# platform_designer_hps_system_hps_0_hps register map
Vendor: default_vendor.com; File version: 0.0
Registers are 32-bit, read-write, reset 0x0 unless marked. A register's access mark holds for its fields unless they carry their own. Offsets are from the block's base; [hi:lo] are bit positions; {n}, {i} and the like mark numbered series; 'fields as' and 'values as' point back to an identical list.

## can0 — Registers in the CAN Controller module NOTE: These descriptions apply only to SoC devices that support the CAN module.
Base 0xFFC00000
Same registers: can1 0xFFC01000
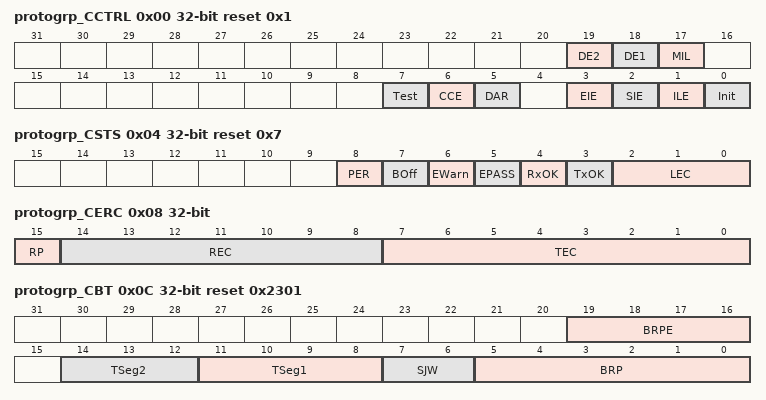
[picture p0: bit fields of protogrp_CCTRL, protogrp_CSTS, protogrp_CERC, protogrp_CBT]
0x00 protogrp_CCTRL reset 0x1 — Control Register
  [19] DE2 — DMA Enable for IF2
    0=Disabled; 1=Enabled
  [18] DE1 — DMA Enable for IF1
    0=Disabled; 1=Enabled
  [17] MIL — Message Object Interrupt Line Enable
    0=Disabled; 1=Enabled
  [7] Test — Test Mode Enable
    0=Disabled; 1=TestMode
  [6] CCE — Configuration Change Enable
    0=NoWrAcc; 1=WrAcc
  [5] DAR — Disable Automatic Retransmission
    0=Enabled; 1=Disabled
  [3] EIE — Error Interrupt Enable
    0=Disabled; 1=Enabled
  [2] SIE — Status Interrupt Enable
    0=Disabled; 1=Enabled
  [1] ILE — Module Interrupt Line Enable
    0=Disabled; 1=Enabled
  [0] Init — Initialization Note: Due to the synchronization mechanism between the two clock domains, there may be a delay until the value written to CCTRL.Init can be read back. Therefore the programmer has to assure that the previous value written to CCTRL.Init has been accepted by reading CCTRL.Init before setting CCTRL.Init to a new value. Note: The Bus_Off recovery sequence (see CAN Specification Rev. 2.0) cannot be shortened by setting or resetting CCTRL.Init. If the device goes Bus_Off, it will set CCTRL.Init of its own accord, stopping all bus activities. Once CCTRL.Init has been cleared by the CPU, the device will then wait for 129 occurrences of Bus Idle (129 * 11 consecutive recessive bits) before resuming normal operations. At the end of the Bus_Off recovery sequence, the Error Management Counters will be reset. During the waiting time after the resetting of CCTRL.Init, each time a sequence of 11 recessive bits has been monitored, a Bit0Error code is written to the Status Register, enabling the CPU to readily check up whether the CAN bus is stuck at dominant or continuously disturbed and to monitor the proceeding of the us_Off recovery sequence.
    0=Normal; 1=Start
0x04 protogrp_CSTS ro reset 0x7 — Status Register
  [8] PER — Parity Error Detected
    0=None; 1=ErrorDetected
  [7] BOff — Bus_Off Status
    0=NotBusOff; 1=BusOff
  [6] EWarn — Warning Status
    0=BelowLimit; 1=AboveLimit
  [5] EPASS — Error Passive
    0=Active; 1=Passive
  [4] RxOK — Received a Message Successfully
    0=NoRxOk; 1=RxOk
  [3] TxOK — Transmitted a Message Successfully
    0=NoTxOk; 1=TxOk
  [2:0] LEC — The LEC field holds a code which indicates the type of the last error to occur on the CAN bus. This field will be cleared to 0 when a message has been transferred (reception or transmission) without error.
    0=NoError; 1=StuffError; 2=FormError; 3=AckError; 4=Bit1Error; 5=Bit0Error; 6=CRCError; 7=NoChange
0x08 protogrp_CERC ro — Error Counter Register
  [15] RP
    0=Below; 1=Reached
  [14:8] REC — Actual state of the Receive Error Counter. Values between 0 and 127.
  [7:0] TEC — Actual state of the Transmit Error Counter. Values between 0 and 255.
0x0C protogrp_CBT reset 0x2301 — This register is only writable if bits CCTRL.CCE and CCTRL.Init are set. The CAN bit time may be programed in the range of [4 .. 25] time quanta. The CAN time quantum may be programmed in the range of [1 .. 1024] CAN_CLK periods. For details see Application Note 001 "Configuration of Bit Timing". The actual interpretation by the hardware of this value is such that one more than the value programmed here is used. TSeg1 is the sum of Prop_Seg and Phase_Seg1. TSeg2 is Phase_Seg2. Therefore the length of the bit time is (programmed values) [TSeg1 + TSeg2 + 3] tq or (functional values) [Sync_Seg + Prop_Seg + Phase_Seg1 + Phase_Seg2] tq.
  [19:16] BRPE — By programming BRPE the Baud Rate Prescaler can be extended to values up to 1023. The actual interpretation by the hardware is that one more than the value programmed by BRPE (MSBs) and BRP (LSBs) is used.
  [14:12] TSeg2 — Valid values for TSeg2 are [0 .. 7].
  [11:8] TSeg1 — Valid values for TSeg1 are [1 .. 15].
  [7:6] SJW — Valid programmed values are [0 .. 3]. The actual interpretation by the hardware of this value is such that one more than the value programmed here is used.
  [5:0] BRP — The value by which the oscillator frequency is divided for generating the bit time quanta. The bit time is built up from a multiple of this quanta. Valid values for the Baud Rate Prescaler are [0 .. 63]. The actual interpretation by the hardware of this value is such that one more than the value programmed here is used.
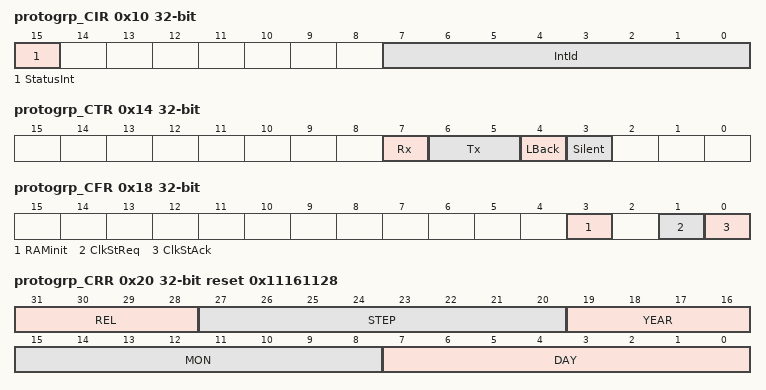
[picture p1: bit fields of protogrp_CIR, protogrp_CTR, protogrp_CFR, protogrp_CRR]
0x10 protogrp_CIR ro — If several interrupts are pending, the CAN Interrupt Register will point to the pending interrupt with the highest priority, disregarding their chronological order. An interrupt remains pending until the CPU has cleared it. If IntID is different from 0x00 and CCTRL.MIL is set, the interrupt port CAN_INT_MO is active. The interrupt port remains active until IntID is back to value 0x00 (the cause of the interrupt is reset) or until CCTRL.MIL is reset. If CCTRL.ILE is set and CCTRL.MIL is reseted the Message Object interrupts will be routed to interrupt port CAN_INT_STATUS. The interrupt port remains active until IntID is back to value 0x00 (the cause of the interrupt is reset) or until CCTRL.MIL is set or CCTRL.ILE is reset. The Message Object's interrupt priority decreases with increasing message number. A message interrupt is cleared by clearing the Message Object's IntPnd bit.
  [15] StatusInt — The Status Interrupt is cleared by reading the Status Register.
  [7:0] IntId — 0x00 No Message Object interrupt is pending. 0x01-0x80 Number of Message Object which caused the interrupt. 0x81-0xFF unused.
0x14 protogrp_CTR (reset mask 0xFFFFFF7F) — The Test Mode is entered by setting bit CCTRL.Test to one. In Test Mode the bits EXL, Tx1, Tx0, LBack and Silent in the Test Register are writable. Bit Rx monitors the state of pin CAN_RXD and therefore is only readable. All Test Register functions are disabled when bit Test is reset to zero. Loop Back Mode and CAN_TXD Control Mode are hardware test modes, not to be used by application programs. Note: This register is only writable if bit CCTRL.Test is set.
  [7] Rx ro — Monitors the actual value of the CAN_RXD pin.
    0=Dominant; 1=Recessive
  [6:5] Tx — Controls CAN_TXD pin. Setting to non-zero disturbs message transfer.
    0=Reset; 1=Sample; 2=Dominant; 3=Recessive
  [4] LBack — Loop Back Mode
    0=Disabled; 1=Enabled
  [3] Silent — Silent Mode
    0=Normal; 1=Silent
0x18 protogrp_CFR — The Function Register controls the features RAM_Initialisation and Power_Down also by application register. The CAN module can be prepared for Power_Down by setting the port CAN_CLKSTOP_REQ to one or writing to CFR.ClkStReq a one. The power down state is left by setting port CAN_CLKSTOP_REQ to zero or writing to CFR.ClkStReq a zero, acknowledged by CAN_CLKSTOP_ACK is going to zero as well as CFR.ClkStAck. The CCTRL.Init bit is left one and has to be written by the application to re-enable CAN transfers. Note: It's recommended to use either the ports CAN_CLKSTOP_REQ and CAN_CLKSTOP_ACK or the CCTRL.ClkStReq and CFR.ClkStAck. The application CFR.ClkStReq showsalso the actual status of the portCAN_CLKSTOP_REQ.
  [3] RAMinit — Request for automatic RAM Initialization
    0=NoAuto; 1=StartAuto
  [1] ClkStReq — Clock Stop Request
  [0] ClkStAck ro — Clock Stop Acknowledgement
0x20 protogrp_CRR ro reset 0x11161128 — Core Release Register
  [31:28] REL, [27:20] STEP, [19:16] YEAR, [15:8] MON, [7:0] DAY
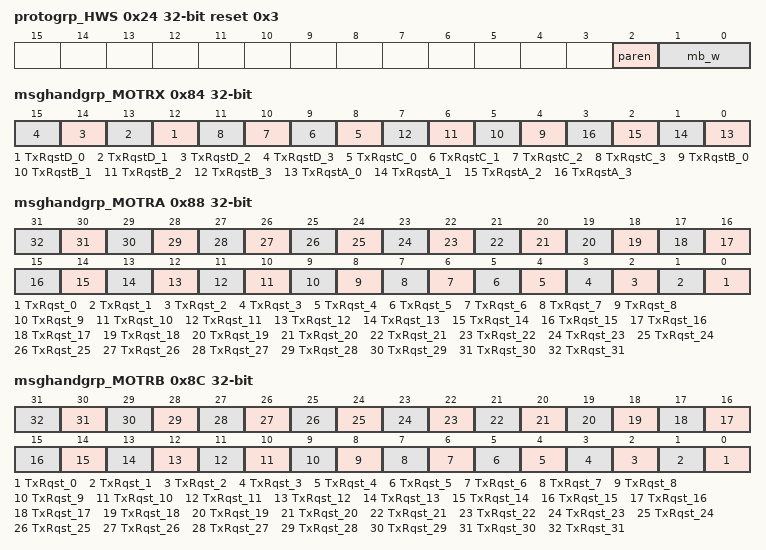
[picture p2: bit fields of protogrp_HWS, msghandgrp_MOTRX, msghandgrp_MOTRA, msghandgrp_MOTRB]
0x24 protogrp_HWS ro reset 0x3 — Hardware Configuration Status Register
  [2] paren — Parity Generation
    0=NotPresent; 1=Present
  [1:0] mb_w — Message Buffer Count
    0=MsgObjs16; 1=MsgObjs32; 2=MsgObjs64; 3=MsgObjs128
0x84 msghandgrp_MOTRX ro — Reading this register allows the CPU to quickly detect if any of the transmission request bits in each of the MOTRA, MOTRB, MOTRC, and MOTRD Transmission Request Registers are set.
  [all] fields
    0=NotWaiting; 1=Pending
  [n+12] TxRqstD_{n} (n=0..3) — Each bit in this field is a logical OR of a byte of the MOTRD register. Array index i corresponds to byte i of the MOTRD register.
  [n+8] TxRqstC_{n} (n=0..3) — Each bit in this field is a logical OR of a byte of the MOTRC register. Array index i corresponds to byte i of the MOTRC register.
  [n+4] TxRqstB_{n} (n=0..3) — Each bit in this field is a logical OR of a byte of the MOTRB register. Array index i corresponds to byte i of the MOTRB register.
  [n] TxRqstA_{n} (n=0..3) — Each bit in this field is a logical OR of a byte of the MOTRA register. Array index i corresponds to byte i of the MOTRA register.
0x88 msghandgrp_MOTRA ro — Transmission request bits for Message Objects 1 to 32. By reading the TxRqst bits, the CPU can check for which Message Object a Transmission Request is pending. The TxRqst bit of a specific Message Object can be set/reset by the CPU via the IFx Message Interface Registers or set by the Message Handler after reception of a Remote Frame or reset by the Message Handler after a successful transmission.
  [all] fields
    0=NotWaiting; 1=Pending
  [n] TxRqst_{n} (n=0..31) — Transmission request bits for Message Objects 1 to 32. Array index i corresponds to Message Object i+1.
0x8C msghandgrp_MOTRB ro — Transmission request bits for Message Objects 33 to 64. By reading the TxRqst bits, the CPU can check for which Message Object a Transmission Request is pending. The TxRqst bit of a specific Message Object can be set/reset by the CPU via the IFx Message Interface Registers or set by the Message Handler after reception of a Remote Frame or reset by the Message Handler after a successful transmission.
  [all] fields
    0=NotWaiting; 1=Pending
  [n] TxRqst_{n} (n=0..31) — Transmission request bits for Message Objects 33 to 64. Array index i corresponds to Message Object i+33.
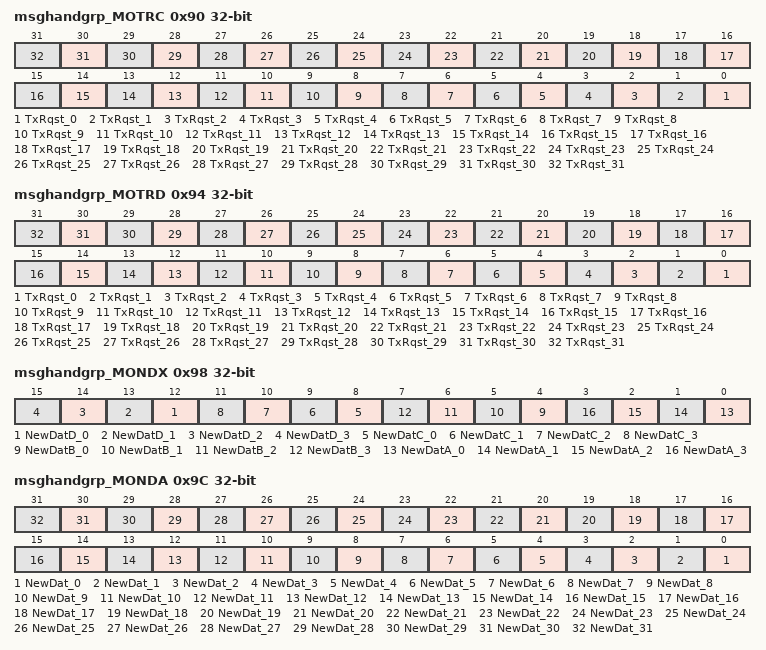
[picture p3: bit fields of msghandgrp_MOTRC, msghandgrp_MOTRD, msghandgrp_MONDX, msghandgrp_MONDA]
0x90 msghandgrp_MOTRC ro — Transmission request bits for Message Objects 65 to 96. By reading the TxRqst bits, the CPU can check for which Message Object a Transmission Request is pending. The TxRqst bit of a specific Message Object can be set/reset by the CPU via the IFx Message Interface Registers or set by the Message Handler after reception of a Remote Frame or reset by the Message Handler after a successful transmission.
  [all] fields
    0=NotWaiting; 1=Pending
  [n] TxRqst_{n} (n=0..31) — Transmission request bits for Message Objects 65 to 96. Array index i corresponds to Message Object i+65.
0x94 msghandgrp_MOTRD ro — Transmission request bits for Message Objects 97 to 128. By reading the TxRqst bits, the CPU can check for which Message Object a Transmission Request is pending. The TxRqst bit of a specific Message Object can be set/reset by the CPU via the IFx Message Interface Registers or set by the Message Handler after reception of a Remote Frame or reset by the Message Handler after a successful transmission.
  [all] fields
    0=NotWaiting; 1=Pending
  [n] TxRqst_{n} (n=0..31) — Transmission request bits for Message Objects 97 to 128. Array index i corresponds to Message Object i+97.
0x98 msghandgrp_MONDX ro — Reading this register allows the CPU to quickly detect if any of the new data bits in each of the MONDA, MONDB, MONDC, and MONDD New Data Registers are set.
  [all] fields
    0=NotWritten; 1=Written
  [n+12] NewDatD_{n} (n=0..3) — Each bit in this field is a logical OR of a byte of the MONDD register. Array index i corresponds to byte i of the MONDD register.
  [n+8] NewDatC_{n} (n=0..3) — Each bit in this field is a logical OR of a byte of the MONDC register. Array index i corresponds to byte i of the MONDC register.
  [n+4] NewDatB_{n} (n=0..3) — Each bit in this field is a logical OR of a byte of the MONDB register. Array index i corresponds to byte i of the MONDB register.
  [n] NewDatA_{n} (n=0..3) — Each bit in this field is a logical OR of a byte of the MONDA register. Array index i corresponds to byte i of the MONDA register.
0x9C msghandgrp_MONDA ro — New data bits for Message Objects 1 to 32. By reading the NewDat bits, the CPU can check for which Message Object the data portion was updated. The NewDat bit of a specific Message Object can be set/reset by the CPU via the IFx Message Interface Registers or set by the Message Handler after reception of a Data Frame or reset by the Message Handler at start of a transmission.
  [all] fields
    0=NotWritten; 1=Written
  [n] NewDat_{n} (n=0..31) — New data bits for Message Objects 1 to 32. Array index i corresponds to Message Object i+1.
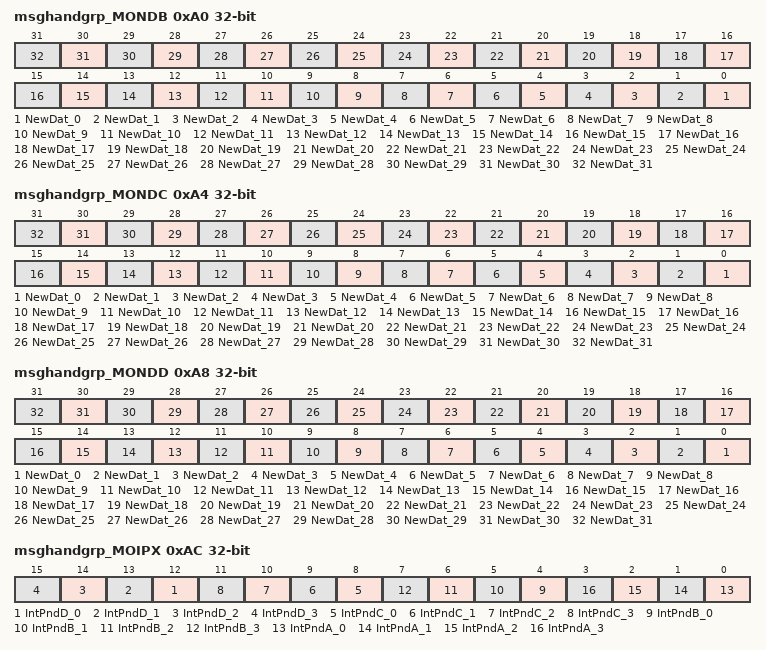
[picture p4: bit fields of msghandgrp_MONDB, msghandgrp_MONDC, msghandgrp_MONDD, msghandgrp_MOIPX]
0xA0 msghandgrp_MONDB ro — New data bits for Message Objects 33 to 64. By reading the NewDat bits, the CPU can check for which Message Object the data portion was updated. The NewDat bit of a specific Message Object can be set/reset by the CPU via the IFx Message Interface Registers or set by the Message Handler after reception of a Data Frame or reset by the Message Handler at start of a transmission.
  [all] fields
    0=NotWritten; 1=Written
  [n] NewDat_{n} (n=0..31) — New data bits for Message Objects 33 to 64. Array index i corresponds to Message Object i+33.
0xA4 msghandgrp_MONDC ro — New data bits for Message Objects 65 to 96. By reading the NewDat bits, the CPU can check for which Message Object the data portion was updated. The NewDat bit of a specific Message Object can be set/reset by the CPU via the IFx Message Interface Registers or set by the Message Handler after reception of a Data Frame or reset by the Message Handler at start of a transmission.
  [all] fields
    0=NotWritten; 1=Written
  [n] NewDat_{n} (n=0..31) — New data bits for Message Objects 65 to 96. Array index i corresponds to Message Object i+65.
0xA8 msghandgrp_MONDD ro — New data bits for Message Objects 97 to 128. By reading the NewDat bits, the CPU can check for which Message Object the data portion was updated. The NewDat bit of a specific Message Object can be set/reset by the CPU via the IFx Message Interface Registers or set by the Message Handler after reception of a Data Frame or reset by the Message Handler at start of a transmission.
  [all] fields
    0=NotWritten; 1=Written
  [n] NewDat_{n} (n=0..31) — New data bits for Message Objects 97 to 128. Array index i corresponds to Message Object i+97.
0xAC msghandgrp_MOIPX ro — Reading this register allows the CPU to quickly detect if any of the interrupt pending bits in each of the MOIPA, MOIPB, MOIPC, and MOIPD Interrupt Pending Registers are set.
  [all] fields
    0=NotSrc; 1=Src
  [n+12] IntPndD_{n} (n=0..3) — Each bit in this field is a logical OR of a byte of the MOIPD register. Array index i corresponds to byte i of the MOIPD register.
  [n+8] IntPndC_{n} (n=0..3) — Each bit in this field is a logical OR of a byte of the MOIPC register. Array index i corresponds to byte i of the MOIPC register.
  [n+4] IntPndB_{n} (n=0..3) — Each bit in this field is a logical OR of a byte of the MOIPB register. Array index i corresponds to byte i of the MOIPB register.
  [n] IntPndA_{n} (n=0..3) — Each bit in this field is a logical OR of a byte of the MOIPA register. Array index i corresponds to byte i of the MOIPA register.
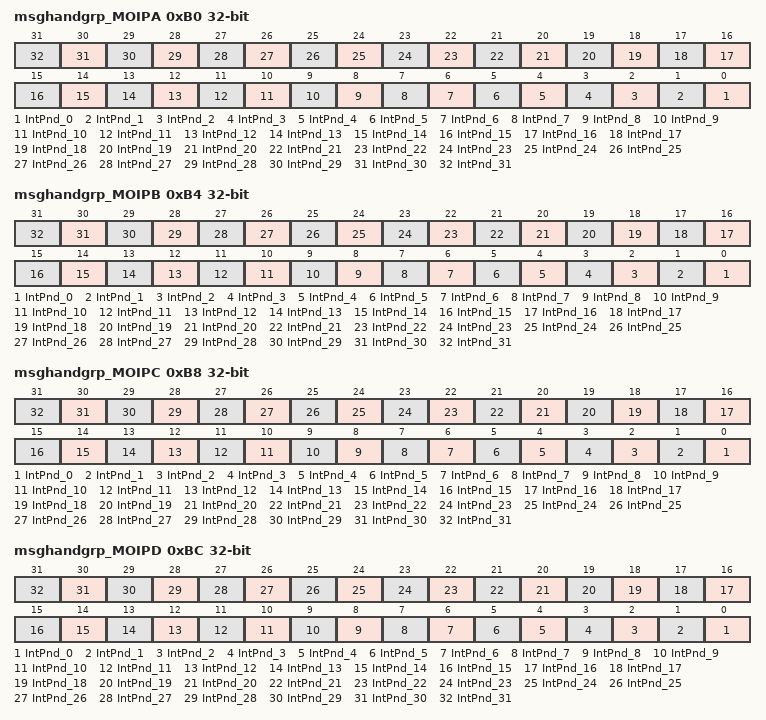
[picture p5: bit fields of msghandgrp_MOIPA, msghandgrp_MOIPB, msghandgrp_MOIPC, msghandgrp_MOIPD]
0xB0 msghandgrp_MOIPA ro — Interrupt pending bits for Message Objects 1 to 32. By reading the IntPnd bits, the CPU can check for which Message Object an interrupt is pending. The IntPnd bit of a specific Message Object can be set/reset by the CPU via the IFx Message Interface Registers or set by the Message Handler after reception or after a successful transmission of a frame. This will also affect the valid of IntID in the Interrupt Register.
  [all] fields
    0=NotSrc; 1=Src
  [n] IntPnd_{n} (n=0..31) — Interrupt pending bits for Message Objects 1 to 32. Array index i corresponds to Message Object i+1.
0xB4 msghandgrp_MOIPB ro — Interrupt pending bits for Message Objects 33 to 64. By reading the IntPnd bits, the CPU can check for which Message Object an interrupt is pending. The IntPnd bit of a specific Message Object can be set/reset by the CPU via the IFx Message Interface Registers or set by the Message Handler after reception or after a successful transmission of a frame. This will also affect the valid of IntID in the Interrupt Register.
  [all] fields
    0=NotSrc; 1=Src
  [n] IntPnd_{n} (n=0..31) — Interrupt pending bits for Message Objects 33 to 64. Array index i corresponds to Message Object i+33.
0xB8 msghandgrp_MOIPC ro — Interrupt pending bits for Message Objects 65 to 96. By reading the IntPnd bits, the CPU can check for which Message Object an interrupt is pending. The IntPnd bit of a specific Message Object can be set/reset by the CPU via the IFx Message Interface Registers or set by the Message Handler after reception or after a successful transmission of a frame. This will also affect the valid of IntID in the Interrupt Register.
  [all] fields
    0=NotSrc; 1=Src
  [n] IntPnd_{n} (n=0..31) — Interrupt pending bits for Message Objects 65 to 96. Array index i corresponds to Message Object i+65.
0xBC msghandgrp_MOIPD ro — Interrupt pending bits for Message Objects 97 to 128. By reading the IntPnd bits, the CPU can check for which Message Object an interrupt is pending. The IntPnd bit of a specific Message Object can be set/reset by the CPU via the IFx Message Interface Registers or set by the Message Handler after reception or after a successful transmission of a frame. This will also affect the valid of IntID in the Interrupt Register.
  [all] fields
    0=NotSrc; 1=Src
  [n] IntPnd_{n} (n=0..31) — Interrupt pending bits for Message Objects 97 to 128. Array index i corresponds to Message Object i+97.
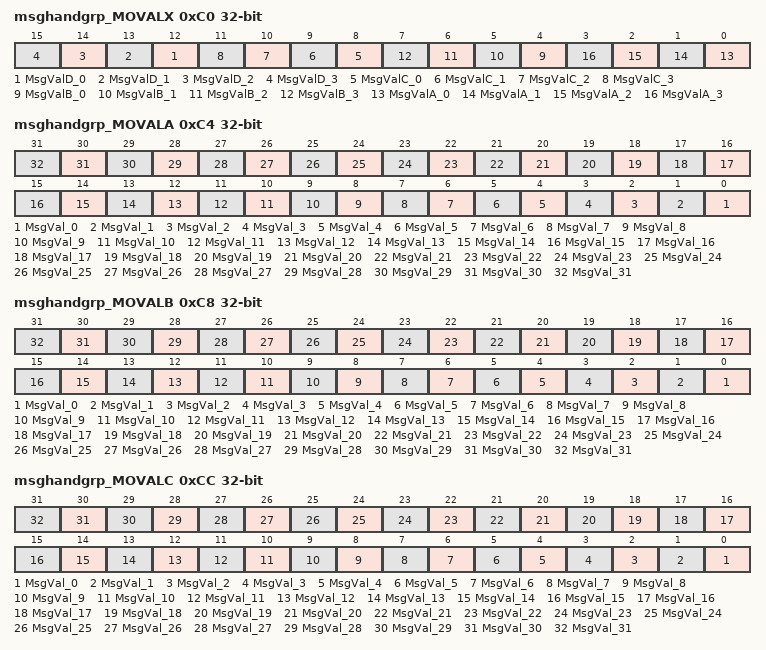
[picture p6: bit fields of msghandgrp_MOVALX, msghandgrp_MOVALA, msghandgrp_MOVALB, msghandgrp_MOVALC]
0xC0 msghandgrp_MOVALX ro — Reading this register allows the CPU to quickly detect if any of the message valid bits in each of the MOVALA, MOVALB, MOVALC, and MOVALD Message Valid Registers are set.
  [all] fields
    0=Ignored; 1=Considered
  [n+12] MsgValD_{n} (n=0..3) — Each bit in this field is a logical OR of a byte of the MOVALD register. Array index i corresponds to byte i of the MOVALD register.
  [n+8] MsgValC_{n} (n=0..3) — Each bit in this field is a logical OR of a byte of the MOVALC register. Array index i corresponds to byte i of the MOVALC register.
  [n+4] MsgValB_{n} (n=0..3) — Each bit in this field is a logical OR of a byte of the MOVALB register. Array index i corresponds to byte i of the MOVALB register.
  [n] MsgValA_{n} (n=0..3) — Each bit in this field is a logical OR of a byte of the MOVALA register. Array index i corresponds to byte i of the MOVALA register.
0xC4 msghandgrp_MOVALA ro — Message valid bits for Message Objects 1 to 32. By reading the MsgVal bits, the CPU can check for which Message Object is valid. The MsgVal bit of a specific Message Object can be set/reset by the CPU via the IFx Message Interface Registers.
  [all] fields
    0=Ignored; 1=Considered
  [n] MsgVal_{n} (n=0..31) — Message valid bits for Message Objects 1 to 32. Array index i corresponds to Message Object i+1.
0xC8 msghandgrp_MOVALB ro — Message valid bits for Message Objects 33 to 64. By reading the MsgVal bits, the CPU can check for which Message Object is valid. The MsgVal bit of a specific Message Object can be set/reset by the CPU via the IFx Message Interface Registers.
  [all] fields
    0=Ignored; 1=Considered
  [n] MsgVal_{n} (n=0..31) — Message valid bits for Message Objects 33 to 64. Array index i corresponds to Message Object i+33.
0xCC msghandgrp_MOVALC ro — Message valid bits for Message Objects 65 to 96. By reading the MsgVal bits, the CPU can check for which Message Object is valid. The MsgVal bit of a specific Message Object can be set/reset by the CPU via the IFx Message Interface Registers.
  [all] fields
    0=Ignored; 1=Considered
  [n] MsgVal_{n} (n=0..31) — Message valid bits for Message Objects 65 to 96. Array index i corresponds to Message Object i+65.
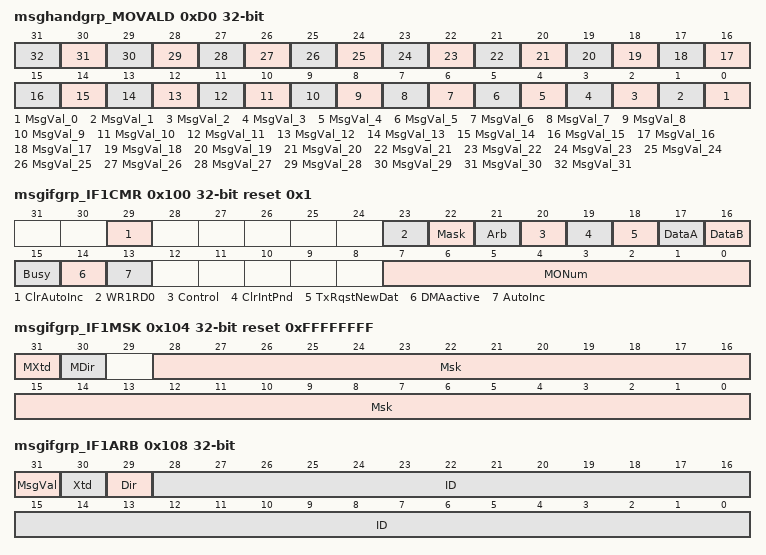
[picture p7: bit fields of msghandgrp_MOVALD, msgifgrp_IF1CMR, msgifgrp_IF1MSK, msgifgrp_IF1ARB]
0xD0 msghandgrp_MOVALD ro — Message valid bits for Message Objects 97 to 128. By reading the MsgVal bits, the CPU can check for which Message Object is valid. The MsgVal bit of a specific Message Object can be set/reset by the CPU via the IFx Message Interface Registers.
  [all] fields
    0=Ignored; 1=Considered
  [n] MsgVal_{n} (n=0..31) — Message valid bits for Message Objects 97 to 128. Array index i corresponds to Message Object i+97.
0x100 msgifgrp_IF1CMR reset 0x1 — The control bits of the IF1/2 Command Register specify the transfer direction and select which portions of the Message Object should be transferred. A message transfer is started as soon as the CPU has written the message number to the low byte of the Command Request Register and IFxCMR.AutoInc is zero. With this write operation, the IFxCMR.Busy bit is automatically set to 1 to notify the CPU that a transfer is in progress. After a wait time of 2 to 8 HOST_CLK periods, the transfer between theInterface Register and the Message RAM has been completed and the IFxCMR.Busy bit is cleared to 0. The upper limit of the wait time occurs when the message transfer coincides with a CAN message transmission, acceptance filtering, or message storage. If the CPU writes to both Command Registers consecutively (requests a second transfer while another transfer is already in progress), the second transfer starts when the first one is completed. Note: While Busy bit of IF1/2 Command Register is one, IF1/2 Register Set is write protected.
  [29] ClrAutoInc — Clear the AutoInc bit without starting a transfer
    0=NoClear; 1=Clear
  [23] WR1RD0 — Write / Read Transfer
    0=Read; 1=Write
  [22] Mask — Write Direction: 0= Mask bits unchanged. 1= transfer Identifier Mask + MDir + MXtd to Message Object. Read Direction: 0= Mask bits unchanged. 1= transfer Identifier Mask + MDir + MXtd to IFxMSK Register.
  [21] Arb — Write Direction: 0= Arbitration bits unchanged. 1= transfer Identifier + Dir + Xtd + MsgVal to Message Object. Read Direction: 0= Arbitration bits unchanged. 1= transfer Identifier + Dir + Xtd + MsgVal to IFxARB Register.
  [20] Control — Write Direction: 0= Control Bits unchanged. 1= transfer Control Bits to Message Object. Note: If IFxCMR.TxRqst/NewDat bit is set, bits IFxMCTR.TxRqst and IFxMCTR.NewDat will be ignored. Read Direction: 0= Control Bits unchanged. 1= transfer Control Bits to IFxMCTR Register.
  [19] ClrIntPnd — Write Direction: Has no influence to Message Object at write transfer. Note: When writing to a Message Object, this bit is ignored and copying of IntPnd flag from IFx Control Register to Message RAM could only be controlled by IFxMTR.IntPnd bit. Read Direction: 0= IntPnd bit remains unchanged. 1= clear IntPnd bit in the Message Object.
  [18] TxRqstNewDat — Write Direction: 0= TxRqst and NewDat bit will be handled according IFxMCTR.NewDat bit and IFxMCTR.TxRqst bit. 1= set TxRqst and NewDat in Message Object to one Note: If a CAN transmission is requested by setting IFxCMR.TxRqst/NewDat, the TxRqst and NewDat bits in the Message Object will be set to one independently of the values in IFxMCTR. Read Direction: 0= NewDat bit remains unchanged. 1= clear NewDat bit in the Message Object. Note: A read access to a Message Object can be combined with the reset of the control bits IntPnd and NewDat. The values of these bits transferred to the IFxMCTR always reflect the status before resetting them.
  [17] DataA — Write Direction: 0= Data Bytes 0-3 unchanged. 1= transfer Data Bytes 0-3 to Message Object. Read Direction: 0= Data Bytes 0-3 unchanged. 1= transfer Data Bytes 0-3 to IFxDA.
  [16] DataB — Write Direction: 0= Data Bytes 4-7 unchanged. 1= transfer Data Bytes 4-7 to Message Object. Read Direction: 0= Data Bytes 4-7 unchanged. 1= transfer Data Bytes 4-7 to IFxDB. Note: The speed of the message transfer does not depend on how many bytes are transferred.
  [15] Busy ro — Busy Flag
    0=Done; 1=Writing
  [14] DMAactive — Activation of DMA feature for subsequent internal IFx Register Set
    0=Passive; 1=Initiated
  [13] AutoInc — Automatic Increment of Message Object Number The behavior of the Message Object Number increment depends on the Transfer Direction, IFxCMR.WR1RD0. * Read: The first transfer will be initiated (Busy Bit will set) at write of IFxCMR.MONum. The Message Object Number will be incremented and the next Message Object will be transferred from Message Object RAM to Interface Registers after a read access of Data-Byte 7. * Write: The first as well as each other transfer will be started after write access to Data- Byte7. The Message Object Number will be incremented after successful transfer from the Interface Registers to the Message Object RAM. Always after successful transfer the Busy Bit will be reset. In combination with DMAactive the port CAN_IFxDMA is set, too. Note: If the direction is configured as Read a write access to Data-Byte 7 will not start any transfer, as well as if the direction is configured as Write a read access to Data-Byte 7 will not start any transfer. At transfer direction Read each read of Data-Byte 7 will start a transfer until IFxCMR.AutoInc is reset. To aware of resetting a NewDat bit of the following message object, the application has to reset IFxCMR.AutoInc before reading the Data-Byte 7 of the last message object which will be read.
    0=Disabled; 1=Enabled
  [7:0] MONum — 0x01-0x80 Valid Message Number, the Message Object in the Message RAM is selected for data transfer (up to 128 MsgObj). 0x00 Not a valid Message Number, interpreted as 0x80. 0x81-0xFF Not a valid Message Number, interpreted as 0x01-0x7F. Note: When an invalid Message Number is written to IFxCMR.MONum which is higher than the last Message Object number, a modulo addressing will occur.When e.g. accessing Message Object 33 in a CAN module with 32 Message Objects only, the Message Object 1 will be accessed instead.
0x104 msgifgrp_IF1MSK reset 0xFFFFFFFF — The Message Object Mask Bits together with the arbitration bits are used for acceptance filtering of incoming messages. Note: While IFxCMR.Busy bit is one, the IF1/2 Register Set is write protected.
  [31] MXtd — When 11-bit (standard) Identifiers are used for a Message Object, the identifiers of received Data Frames are written into bits ID28 to ID18. For acceptance filtering, only these bits together with mask bits Msk28 to Msk18 are considered.
    0=NoAcceptEffect; 1=AcceptEffect
  [30] MDir
    0=NoAcceptEffect; 1=AcceptEffect
  [28:0] Msk — 0 = The corresponding bit in the identifier of the message object cannot inhibit the match in the acceptance filtering. 1 = The corresponding identifier bit is used for acceptance filtering.
0x108 msgifgrp_IF1ARB — The Arbitration Registers ID28-0, Xtd, and Dir are used to define the identifier and type of outgoing messages and are used (together with the mask registers Msk28-0, MXtd, and MDir) for acceptance filtering of incoming messages. A received message is stored into the valid Message Object with matching identifier and Direction=receive (Data Frame) or Direction=transmit (Remote Frame). Extended frames can be stored only in Message Objects with Xtd = one, standard frames in Message Objects with Xtd = zero. If a received message (Data Frame or Remote Frame) matches with more than one valid Message Object, it is stored into that with the lowest message number.
  [31] MsgVal — The CPU must reset the MsgVal bit of all unused Messages Objects during the initialization before it resets bit Init in the CAN Control Register. MsgVal must also be reset if the Messages Object is no longer used in operation. For reconfiguration of Message Objects during normal operation.
    0=Ignored; 1=Considered
  [30] Xtd — Extended Identifier
    0=Standard; 1=Extended
  [29] Dir — Message Direction
    0=Rx; 1=Tx
  [28:0] ID — ID28 - ID0 29-bit Identifier (Extended Frame). ID28 - ID18 11-bit Identifier (Standard Frame).
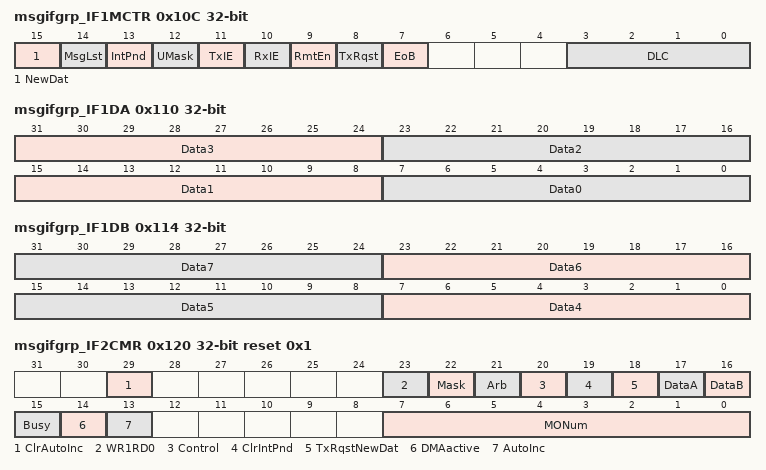
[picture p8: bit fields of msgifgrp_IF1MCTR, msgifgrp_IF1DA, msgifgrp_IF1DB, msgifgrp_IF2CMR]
0x10C msgifgrp_IF1MCTR — The Arbitration Registers ID28-0, Xtd, and Dir are used to define the identifier and type of outgoing messages and are used (together with the mask registers Msk28-0, MXtd, and MDir) for acceptance filtering of incoming messages. A received message is stored into the valid Message Object with matching identifier and Direction=receive (Data Frame) or Direction=transmit (Remote Frame). Extended frames can be stored only in Message Objects with Xtd = one, standard frames in Message Objects with Xtd = zero. If a received message (Data Frame or Remote Frame) matches with more than one valid Message Object, it is stored into that with the lowest message number.
  [15] NewDat — New Data
    0=NotWritten; 1=Written
  [14] MsgLst — Message Lost
    0=NotLost; 1=Lost
  [13] IntPnd — Interrupt Pending
    0=NotSrc; 1=Src
  [12] UMask — Use Acceptance Mask
    0=Ignore; 1=Use
  [11] TxIE — Transmit Interrupt Enable
    0=Unchanged; 1=Set
  [10] RxIE — Receive Interrupt Enable
    0=Unchanged; 1=Set
  [9] RmtEn — Remote Enable
    0=Unchanged; 1=Set
  [8] TxRqst — Transmit Request
    0=NotWaiting; 1=Pending
  [7] EoB — Note: This bit is used to concatenate two or more Message Objects (up to 128) to build a FIFO Buffer. For single Message Objects (not belonging to a FIFO Buffer) this bit must always be set to one.
    0=NotLast; 1=SingleOrLast
  [3:0] DLC — 0-8 Data Frame has 0-8 data bytes. 9-15 Data Frame has 8 data bytes. Note: The Data Length Code of a Message Object must be defined the same as in all the corresponding objects with the same identifier at other nodes. When the Message Handler stores a data frame, it will write the DLC to the value given by the received message.
0x110 msgifgrp_IF1DA — The data bytes of CAN messages are stored in the IF1/2 registers in the following order. In a CAN Data Frame, Data(0) is the first, Data(7) is the last byte to be transmitted or received. In CAN's serial bit stream, the MSB of each byte will be transmitted first.
  [31:24] Data3 — 4th data byte of a CAN Data Frame
  [23:16] Data2 — 3rd data byte of a CAN Data Frame
  [15:8] Data1 — 2nd data byte of a CAN Data Frame
  [7:0] Data0 — 1st data byte of a CAN Data Frame
0x114 msgifgrp_IF1DB — The data bytes of CAN messages are stored in the IF1/2 registers in the following order. In a CAN Data Frame, Data(0) is the first, Data(7) is the last byte to be transmitted or received. In CAN's serial bit stream, the MSB of each byte will be transmitted first.
  [8n-25:8n-32] Data{n} (n=4..7) — {n+1}th data byte of a CAN Data Frame
0x120 msgifgrp_IF2CMR reset 0x1 — The control bits of the IF1/2 Command Register specify the transfer direction and select which portions of the Message Object should be transferred. A message transfer is started as soon as the CPU has written the message number to the low byte of the Command Request Register and IFxCMR.AutoInc is zero. With this write operation, the IFxCMR.Busy bit is automatically set to 1 to notify the CPU that a transfer is in progress. After a wait time of 2 to 8 HOST_CLK periods, the transfer between theInterface Register and the Message RAM has been completed and the IFxCMR.Busy bit is cleared to 0. The upper limit of the wait time occurs when the message transfer coincides with a CAN message transmission, acceptance filtering, or message storage. If the CPU writes to both Command Registers consecutively (requests a second transfer while another transfer is already in progress), the second transfer starts when the first one is completed. Note: While Busy bit of IF1/2 Command Register is one, IF1/2 Register Set is write protected.
  fields as msgifgrp_IF1CMR
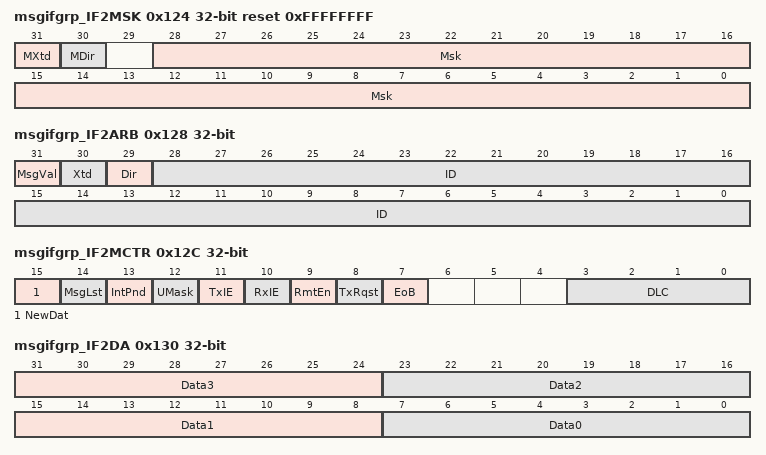
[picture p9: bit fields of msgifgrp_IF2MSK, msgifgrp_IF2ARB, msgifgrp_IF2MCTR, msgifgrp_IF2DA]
0x124 msgifgrp_IF2MSK reset 0xFFFFFFFF — The Message Object Mask Bits together with the arbitration bits are used for acceptance filtering of incoming messages. Note: While IFxCMR.Busy bit is one, the IF1/2 Register Set is write protected.
  fields as msgifgrp_IF1MSK
0x128 msgifgrp_IF2ARB — The Arbitration Registers ID28-0, Xtd, and Dir are used to define the identifier and type of outgoing messages and are used (together with the mask registers Msk28-0, MXtd, and MDir) for acceptance filtering of incoming messages. A received message is stored into the valid Message Object with matching identifier and Direction=receive (Data Frame) or Direction=transmit (Remote Frame). Extended frames can be stored only in Message Objects with Xtd = one, standard frames in Message Objects with Xtd = zero. If a received message (Data Frame or Remote Frame) matches with more than one valid Message Object, it is stored into that with the lowest message number.
  fields as msgifgrp_IF1ARB
0x12C msgifgrp_IF2MCTR — The Arbitration Registers ID28-0, Xtd, and Dir are used to define the identifier and type of outgoing messages and are used (together with the mask registers Msk28-0, MXtd, and MDir) for acceptance filtering of incoming messages. A received message is stored into the valid Message Object with matching identifier and Direction=receive (Data Frame) or Direction=transmit (Remote Frame). Extended frames can be stored only in Message Objects with Xtd = one, standard frames in Message Objects with Xtd = zero. If a received message (Data Frame or Remote Frame) matches with more than one valid Message Object, it is stored into that with the lowest message number.
  fields as msgifgrp_IF1MCTR
0x130 msgifgrp_IF2DA — The data bytes of CAN messages are stored in the IF1/2 registers in the following order. In a CAN Data Frame, Data(0) is the first, Data(7) is the last byte to be transmitted or received. In CAN's serial bit stream, the MSB of each byte will be transmitted first.
  fields as msgifgrp_IF1DA
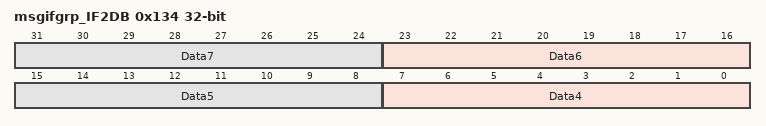
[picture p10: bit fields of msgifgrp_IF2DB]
0x134 msgifgrp_IF2DB — The data bytes of CAN messages are stored in the IF1/2 registers in the following order. In a CAN Data Frame, Data(0) is the first, Data(7) is the last byte to be transmitted or received. In CAN's serial bit stream, the MSB of each byte will be transmitted first.
  fields as msgifgrp_IF1DB
